VERSION ""

NS_ :

BS_:

BU_:

BO_ 1984 Message_LWS_CONFIG: 2 Vector__XXX
 SG_ RES : 4|12@1+ (1,0) [0|4095] "" Vector__XXX
 SG_ CCW : 0|4@1+ (1,0) [0|15] "" Vector__XXX

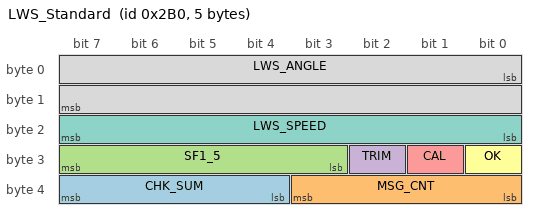
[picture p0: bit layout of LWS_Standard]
BO_ 688 LWS_Standard: 5 Vector__XXX
 SG_ CHK_SUM : 36|4@1+ (1,0) [0|15] "" Vector__XXX
 SG_ MSG_CNT : 32|4@1+ (1,0) [0|15] "" Vector__XXX
 SG_ SF1_5 : 27|5@1+ (1,0) [0|31] "" Vector__XXX
 SG_ TRIM : 26|1@1+ (1,0) [0|1] "" Vector__XXX
 SG_ CAL : 25|1@1+ (1,0) [0|1] "" Vector__XXX
 SG_ OK : 24|1@1+ (1,0) [0|1] "" Vector__XXX
 SG_ LWS_SPEED : 16|8@1+ (4,0) [0|1016] "°/s" Vector__XXX
 SG_ LWS_ANGLE : 0|16@1- (0.1,0) [-780|780] "°" Vector__XXX

BA_DEF_  "BusType" STRING ;
BA_DEF_DEF_  "BusType" "CAN";
